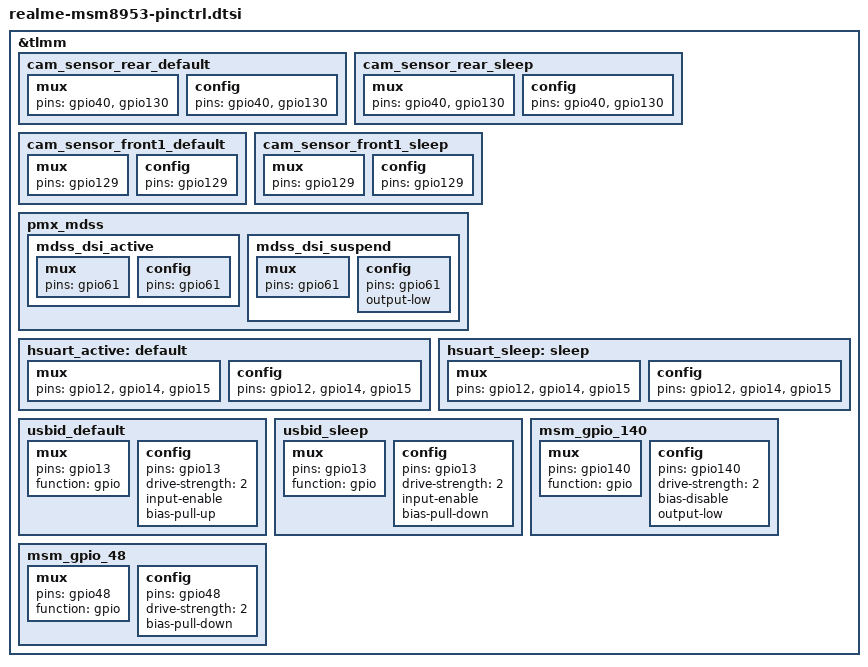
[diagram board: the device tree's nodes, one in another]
/*
 * Copyright (c) 2015-2018, The Linux Foundation. All rights reserved.
 *
 * This program is free software; you can redistribute it and/or modify
 * it under the terms of the GNU General Public License version 2 and
 * only version 2 as published by the Free Software Foundation.
 *
 * This program is distributed in the hope that it will be useful,
 * but WITHOUT ANY WARRANTY; without even the implied warranty of
 * MERCHANTABILITY or FITNESS FOR A PARTICULAR PURPOSE.  See the
 * GNU General Public License for more details.
 */

&tlmm {
	cam_sensor_rear_default: cam_sensor_rear_default {
		mux {
			pins = "gpio40", "gpio130";
		};

		config {
			pins = "gpio40", "gpio130";
		};
	};

	cam_sensor_rear_sleep: cam_sensor_rear_sleep {
		mux {
			pins = "gpio40", "gpio130";
		};

		config {
			pins = "gpio40", "gpio130";
		};
	};

	cam_sensor_front1_default: cam_sensor_front1_default {
		mux {
			pins = "gpio129";
		};

		config {
			pins = "gpio129";
		};
	};

	cam_sensor_front1_sleep: cam_sensor_front1_sleep {
		mux {
			pins = "gpio129";
		};

		config {
			pins = "gpio129";
		};
	};	

	pmx_mdss: pmx_mdss {
		mdss_dsi_active: mdss_dsi_active {
			mux {
				pins = "gpio61";
			};

			config {
				pins = "gpio61";
			};
		};

		mdss_dsi_suspend: mdss_dsi_suspend {
			mux {
				pins = "gpio61";
			};

			config {
				pins = "gpio61";
				output-low;
			};
		};
	};

	hsuart_active: default {
		mux {
			pins = "gpio12", "gpio14", "gpio15";
		};

		config {
			pins = "gpio12", "gpio14", "gpio15";
		};
	};

	hsuart_sleep: sleep {
		mux {
			pins = "gpio12", "gpio14", "gpio15";
		};

		config {
			pins = "gpio12", "gpio14", "gpio15";
		};
	};

	usbid_default: usbid_default {
		mux {
			pins = "gpio13";
			function = "gpio";
		};
		config {
			pins = "gpio13";
			drive-strength = <2>;
			input-enable;
			bias-pull-up;
		};
	};

	usbid_sleep: usbid_sleep {
		mux {
			pins = "gpio13";
			function = "gpio";
		};
		config {
			pins = "gpio13";
			drive-strength = <2>;
			input-enable;
			bias-pull-down;
		};
	};

	msm_gpio_140: msm_gpio_140 {
		mux {
			pins = "gpio140";
			function = "gpio";
		};

		config {
			pins = "gpio140";
			drive-strength = <2>;
			bias-disable;
			output-low;
		};
	};

	msm_gpio_48: msm_gpio_48 {
		mux {
			pins = "gpio48";
			function = "gpio";
		};

		config {
			pins = "gpio48";
			drive-strength = <2>;
			bias-pull-down;
		};
	};
};
